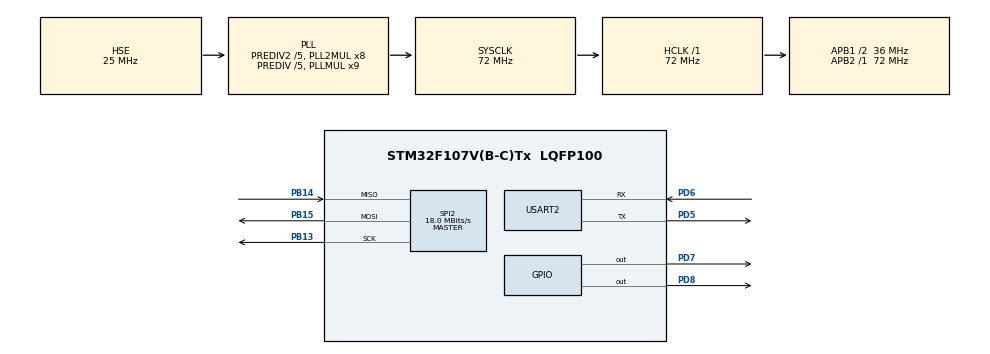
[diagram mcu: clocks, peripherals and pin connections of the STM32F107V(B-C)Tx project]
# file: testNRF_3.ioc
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Mcu.Family=STM32F1
Mcu.Name=STM32F107V(B-C)Tx
Mcu.Package=LQFP100
NVIC.PriorityGroup=NVIC_PRIORITYGROUP_4
OSC_IN.Mode=HSE-External-Oscillator
OSC_IN.Signal=RCC_OSC_IN
OSC_OUT.Mode=HSE-External-Oscillator
OSC_OUT.Signal=RCC_OSC_OUT
PB13.Mode=Full_Duplex_Master
PB13.Signal=SPI2_SCK
PB14.Mode=Full_Duplex_Master
PB14.Signal=SPI2_MISO
PB15.Mode=Full_Duplex_Master
PB15.Signal=SPI2_MOSI
PD5.Mode=Asynchronous
PD5.Signal=USART2_TX
PD6.Mode=Asynchronous
PD6.Signal=USART2_RX
PD7.GPIO_Speed=GPIO_SPEED_HIGH
PD7.Signal=GPIO_Output
PD8.GPIO_Speed=GPIO_SPEED_HIGH
PD8.Signal=GPIO_Output
ProjectManager.TargetToolchain=MDK-ARM V5
RCC.AHBFreq_Value=72000000
RCC.APB1CLKDivider=RCC_HCLK_DIV2
RCC.APB1Freq_Value=36000000
RCC.APB1TimFreq_Value=72000000
RCC.APB2Freq_Value=72000000
RCC.APB2TimFreq_Value=72000000
RCC.HCLKFreq_Value=72000000
RCC.HSEDivPLL=RCC_HSE_PREDIV_DIV5
RCC.HSE_VALUE=25000000
RCC.HSIState=RCC_HSI_ON
RCC.PLLMUL=RCC_PLL_MUL9
RCC.PLLSourceVirtual=RCC_PLLSOURCE_HSE
RCC.Prediv1Source=RCC_PREDIV1_SOURCE_PLL2
RCC.Prediv2=RCC_HSE_PREDIV2_DIV5
RCC.SYSCLKFreq_VALUE=72000000
RCC.SYSCLKSource=RCC_SYSCLKSOURCE_PLLCLK
RCC.USBFreq_Value=48000000
SPI2.CalculateBaudRate=18.0 MBits/s
SPI2.Mode=SPI_MODE_MASTER
board=testNRF_3

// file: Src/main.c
/**
  ******************************************************************************
  * File Name          : main.c
  * Description        : Main program body
  ******************************************************************************
  *
  * COPYRIGHT(c) 2016 STMicroelectronics
  *
  * Redistribution and use in source and binary forms, with or without modification,
  * are permitted provided that the following conditions are met:
  *   1. Redistributions of source code must retain the above copyright notice,
  *      this list of conditions and the following disclaimer.
  *   2. Redistributions in binary form must reproduce the above copyright notice,
  *      this list of conditions and the following disclaimer in the documentation
  *      and/or other materials provided with the distribution.
  *   3. Neither the name of STMicroelectronics nor the names of its contributors
  *      may be used to endorse or promote products derived from this software
  *      without specific prior written permission.
  *
  * THIS SOFTWARE IS PROVIDED BY THE COPYRIGHT HOLDERS AND CONTRIBUTORS "AS IS"
  * AND ANY EXPRESS OR IMPLIED WARRANTIES, INCLUDING, BUT NOT LIMITED TO, THE
  * IMPLIED WARRANTIES OF MERCHANTABILITY AND FITNESS FOR A PARTICULAR PURPOSE ARE
  * DISCLAIMED. IN NO EVENT SHALL THE COPYRIGHT HOLDER OR CONTRIBUTORS BE LIABLE
  * FOR ANY DIRECT, INDIRECT, INCIDENTAL, SPECIAL, EXEMPLARY, OR CONSEQUENTIAL
  * DAMAGES (INCLUDING, BUT NOT LIMITED TO, PROCUREMENT OF SUBSTITUTE GOODS OR
  * SERVICES; LOSS OF USE, DATA, OR PROFITS; OR BUSINESS INTERRUPTION) HOWEVER
  * CAUSED AND ON ANY THEORY OF LIABILITY, WHETHER IN CONTRACT, STRICT LIABILITY,
  * OR TORT (INCLUDING NEGLIGENCE OR OTHERWISE) ARISING IN ANY WAY OUT OF THE USE
  * OF THIS SOFTWARE, EVEN IF ADVISED OF THE POSSIBILITY OF SUCH DAMAGE.
  *
  ******************************************************************************
  */
#include "stm32f1xx_hal.h"
#include <nRF24L01p.h>
#include <string.h>

SPI_HandleTypeDef hspi2;

UART_HandleTypeDef huart2;

/* USER CODE BEGIN PV */
/* Private variables ---------------------------------------------------------*/

/* USER CODE END PV */

void SystemClock_Config(void);
static void MX_GPIO_Init(void);
static void MX_SPI2_Init(void);
static void MX_USART2_UART_Init(void);

/* USER CODE BEGIN PFP */
/* Private function prototypes -----------------------------------------------*/
const bool FAST_Speed = true;
const bool LOW_Speed = false;
/* USER CODE END PFP */

uint8_t dataRead[32];

int main(void)
{

  /* MCU Configuration----------------------------------------------------------*/

  /* Reset of all peripherals, Initializes the Flash interface and the Systick. */
  HAL_Init();

  /* Configure the system clock */
  SystemClock_Config();

  /* Initialize all configured peripherals */
  MX_GPIO_Init();
  MX_SPI2_Init();
  MX_USART2_UART_Init();

  /* USER CODE BEGIN 2 */

	/* ----------    NRF4L01p  Set Up  ----------------- */
	initFirst();
	channel(30);
	RXaddress("ABCDE");
	TXaddress("EDCBA");
	init();

  /* USER CODE END 2 */

  /* Infinite loop */
  /* USER CODE BEGIN WHILE */
	char message[32];
	char messageSend[] ="s02ie";

  while (1)
  {
  /* USER CODE END WHILE */
				if(available() == true){

						/*------   read     -------- */
						read(); // read Data to buffer
						int sizeStr = rxPL(message); // move data from buffer to char array

						while(__HAL_UART_GET_FLAG(&huart2,UART_FLAG_TC)==RESET);   // print via uart2
						HAL_UART_Transmit(&huart2, (uint8_t*) message , sizeStr , 500);
						//HAL_Delay(300);

						//		message[0] = 0;

						/*--------------  transmit   -------------*/

						txPL(messageSend); // send Data to buffer
						send(FAST_Speed); // send Data from buffer to another device [ FAST_Speed is Define in this file (It's 1) ]

				}

//					txPL(messageSend); // send Data to buffer
//					send(FAST_Speed); // send Data from buffer to another device [ FAST_Speed is Define in this file (It's 1) ]

  }

}

/** System Clock Configuration
*/
void SystemClock_Config(void)
{

  RCC_OscInitTypeDef RCC_OscInitStruct;
  RCC_ClkInitTypeDef RCC_ClkInitStruct;

  RCC_OscInitStruct.OscillatorType = RCC_OSCILLATORTYPE_HSE;
  RCC_OscInitStruct.HSEState = RCC_HSE_ON;
  RCC_OscInitStruct.HSEPredivValue = RCC_HSE_PREDIV_DIV5;
  RCC_OscInitStruct.Prediv1Source = RCC_PREDIV1_SOURCE_PLL2;
  RCC_OscInitStruct.PLL.PLLState = RCC_PLL_ON;
  RCC_OscInitStruct.PLL.PLLSource = RCC_PLLSOURCE_HSE;
  RCC_OscInitStruct.PLL.PLLMUL = RCC_PLL_MUL9;
  RCC_OscInitStruct.PLL2.PLL2State = RCC_PLL2_ON;
  RCC_OscInitStruct.PLL2.PLL2MUL = RCC_PLL2_MUL8;
  RCC_OscInitStruct.PLL2.HSEPrediv2Value = RCC_HSE_PREDIV2_DIV5;
  HAL_RCC_OscConfig(&RCC_OscInitStruct);

  RCC_ClkInitStruct.ClockType = RCC_CLOCKTYPE_SYSCLK|RCC_CLOCKTYPE_PCLK1;
  RCC_ClkInitStruct.SYSCLKSource = RCC_SYSCLKSOURCE_PLLCLK;
  RCC_ClkInitStruct.AHBCLKDivider = RCC_SYSCLK_DIV1;
  RCC_ClkInitStruct.APB1CLKDivider = RCC_HCLK_DIV2;
  RCC_ClkInitStruct.APB2CLKDivider = RCC_HCLK_DIV1;
  HAL_RCC_ClockConfig(&RCC_ClkInitStruct, FLASH_LATENCY_2);

  HAL_SYSTICK_Config(HAL_RCC_GetHCLKFreq()/1000);

  HAL_SYSTICK_CLKSourceConfig(SYSTICK_CLKSOURCE_HCLK);

  __HAL_RCC_PLLI2S_ENABLE();

  /* SysTick_IRQn interrupt configuration */
  HAL_NVIC_SetPriority(SysTick_IRQn, 0, 0);
}

/* SPI2 init function */
void MX_SPI2_Init(void)
{

  hspi2.Instance = SPI2;
  hspi2.Init.Mode = SPI_MODE_MASTER;
  hspi2.Init.Direction = SPI_DIRECTION_2LINES;
  hspi2.Init.DataSize = SPI_DATASIZE_8BIT;
  hspi2.Init.CLKPolarity = SPI_POLARITY_LOW;
  hspi2.Init.CLKPhase = SPI_PHASE_1EDGE;
  hspi2.Init.NSS = SPI_NSS_SOFT;
  hspi2.Init.BaudRatePrescaler = SPI_BAUDRATEPRESCALER_2;
  hspi2.Init.FirstBit = SPI_FIRSTBIT_MSB;
  hspi2.Init.TIMode = SPI_TIMODE_DISABLED;
  hspi2.Init.CRCCalculation = SPI_CRCCALCULATION_DISABLED;
  hspi2.Init.CRCPolynomial = 10;
  HAL_SPI_Init(&hspi2);

}

/* USART2 init function */
void MX_USART2_UART_Init(void)
{

  huart2.Instance = USART2;
  huart2.Init.BaudRate = 115200;
  huart2.Init.WordLength = UART_WORDLENGTH_8B;
  huart2.Init.StopBits = UART_STOPBITS_1;
  huart2.Init.Parity = UART_PARITY_NONE;
  huart2.Init.Mode = UART_MODE_TX_RX;
  huart2.Init.HwFlowCtl = UART_HWCONTROL_NONE;
  huart2.Init.OverSampling = UART_OVERSAMPLING_16;
  HAL_UART_Init(&huart2);

}

/** Configure pins as
        * Analog
        * Input
        * Output
        * EVENT_OUT
        * EXTI
*/
void MX_GPIO_Init(void)
{

  GPIO_InitTypeDef GPIO_InitStruct;

  /* GPIO Ports Clock Enable */
  __HAL_RCC_GPIOB_CLK_ENABLE();
  __HAL_RCC_GPIOD_CLK_ENABLE();

  /*Configure GPIO pins : PD8 PD7 */
  GPIO_InitStruct.Pin = GPIO_PIN_8|GPIO_PIN_7|GPIO_PIN_9;
  GPIO_InitStruct.Mode = GPIO_MODE_OUTPUT_PP;
  GPIO_InitStruct.Speed = GPIO_SPEED_HIGH;
  HAL_GPIO_Init(GPIOD, &GPIO_InitStruct);

}

/************************ (C) COPYRIGHT STMicroelectronics *****END OF FILE****/
